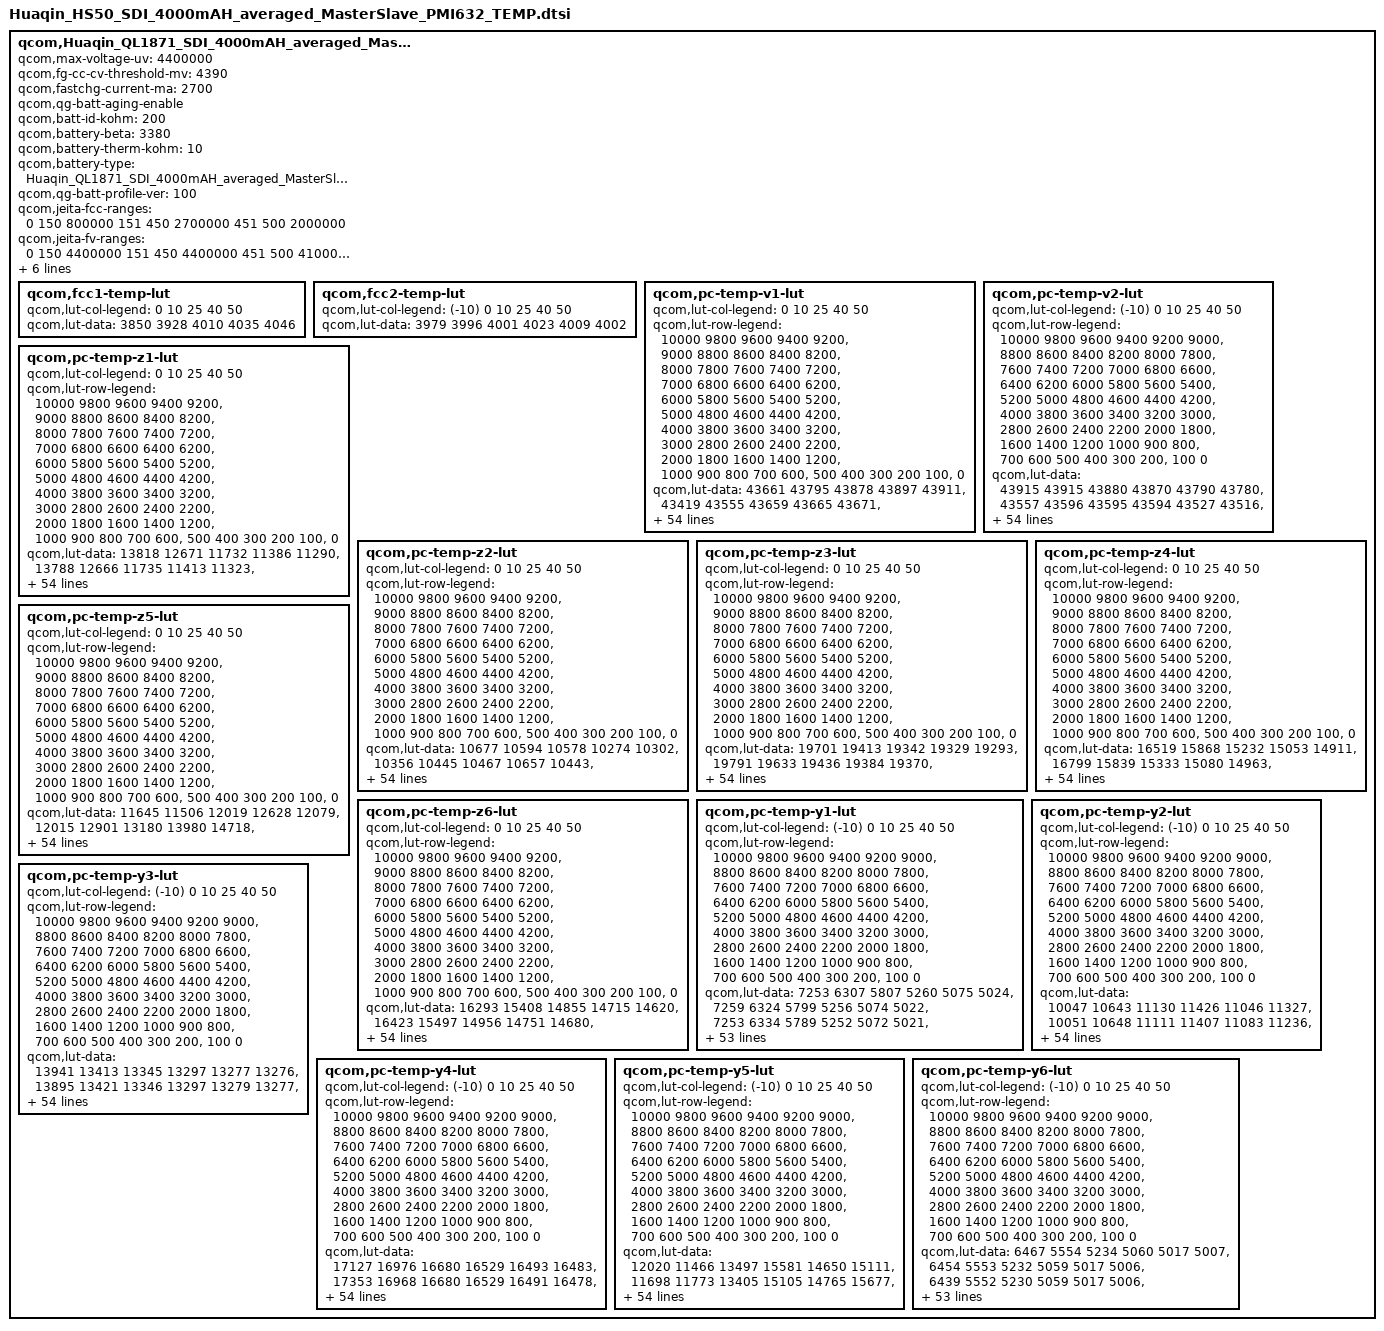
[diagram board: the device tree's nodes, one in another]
qcom,Huaqin_QL1871_SDI_4000mAH_averaged_MasterSlave_PMI632 {
        /* Huaqin_QL1871_SDI_4000mAH_averaged_MasterSlave_PMI632 */
	qcom,max-voltage-uv = <4400000>;
	qcom,fg-cc-cv-threshold-mv = <4390>;
	qcom,fastchg-current-ma = <2700>;
	/* HS60 add for SR-ZQL1695-01-357 Import battery aging by gaochao at 2019/08/29 start */
	qcom,qg-batt-aging-enable;
	/* HS60 add for SR-ZQL1695-01-357 Import battery aging by gaochao at 2019/08/29 end */
	qcom,batt-id-kohm = <200>;
	qcom,battery-beta = <3380>;
	qcom,battery-therm-kohm = <10>;
	qcom,battery-type = "Huaqin_QL1871_SDI_4000mAH_averaged_MasterSlave_PMI632";
	qcom,qg-batt-profile-ver = <100>;

	qcom,jeita-fcc-ranges = <0   150   800000
				 151 450  2700000
				 451 500  2000000>;
	qcom,jeita-fv-ranges =  <0   150  4400000
				 151 450  4400000
				 451 500  4100000>;

	/* HS60 add for SR-ZQL1695-01-357 Import battery aging by gaochao at 2019/08/29 start */
	qcom,vfloat-ranges = <0 299 4400000
	                      300 399 4380000
                              400 699 4360000
                              700 999 4340000
                              1000 9999 4290000>;

	qcom,vbat-rechg-ranges = <0 299 4330000
                                  300 399 4310000
                                  400 699 4290000
                                  700 999 4270000
                                  1000 9999 4220000>;
	/* HS60 add for SR-ZQL1695-01-357 Import battery aging by gaochao at 2019/08/29 end */

	/* COOL = 15 DegC, WARM = 45 DegC */
	qcom,jeita-soft-thresholds = <0x2554 0xFDC>;
	/* COLD = 0 DegC, HOT = 50 DegC */
	/* Huaqin add for HS70-733 modify jeita-hard-thresholds to 50 by qianyingdong at 2019/11/26 start */
	qcom,jeita-hard-thresholds = <0x36B9 0xDBF>;
	/* Huaqin add for HS70-733 modify jeita-hard-thresholds to 50 by qianyingdong at 2019/11/26 end */

	qcom,fcc1-temp-lut {
		qcom,lut-col-legend = <0 10 25 40 50>;
		qcom,lut-data = <3850 3928 4010 4035 4046>;
	};

	qcom,fcc2-temp-lut {
		qcom,lut-col-legend = <(-10) 0 10 25 40 50>;
		qcom,lut-data = <3979 3996 4001 4023 4009 4002>;
	};

	qcom,pc-temp-v1-lut {
		qcom,lut-col-legend = <0 10 25 40 50>;
		qcom,lut-row-legend = <10000 9800 9600 9400 9200>,
			<9000 8800 8600 8400 8200>,
			<8000 7800 7600 7400 7200>,
			<7000 6800 6600 6400 6200>,
			<6000 5800 5600 5400 5200>,
			<5000 4800 4600 4400 4200>,
			<4000 3800 3600 3400 3200>,
			<3000 2800 2600 2400 2200>,
			<2000 1800 1600 1400 1200>,
			<1000 900 800 700 600>,
			<500 400 300 200 100>,
			<0>;
		qcom,lut-data = <43661 43795 43878 43897 43911>,
			<43419 43555 43659 43665 43671>,
			<43173 43315 43415 43437 43445>,
			<42929 43074 43175 43208 43219>,
			<42691 42834 42936 42974 42988>,
			<42457 42597 42698 42737 42755>,
			<42230 42363 42460 42501 42522>,
			<42009 42134 42223 42263 42289>,
			<41794 41908 41992 42030 42057>,
			<41583 41688 41766 41801 41825>,
			<41375 41474 41543 41576 41596>,
			<41175 41266 41327 41353 41373>,
			<40992 41066 41114 41133 41155>,
			<40814 40880 40907 40922 40944>,
			<40604 40693 40702 40719 40738>,
			<40340 40479 40500 40523 40539>,
			<40092 40239 40294 40325 40346>,
			<39926 40032 40093 40127 40158>,
			<39795 39880 39921 39948 39980>,
			<39666 39744 39782 39796 39818>,
			<39534 39595 39634 39644 39656>,
			<39402 39439 39439 39452 39468>,
			<39266 39271 39222 39232 39257>,
			<39126 39058 39036 39041 39065>,
			<38985 38838 38871 38879 38896>,
			<38839 38699 38729 38737 38746>,
			<38696 38607 38618 38619 38623>,
			<38587 38532 38524 38517 38519>,
			<38501 38463 38435 38423 38423>,
			<38430 38400 38351 38334 38331>,
			<38372 38341 38278 38254 38248>,
			<38324 38283 38216 38181 38172>,
			<38282 38231 38161 38116 38102>,
			<38248 38185 38111 38060 38039>,
			<38217 38145 38067 38013 37986>,
			<38183 38107 38025 37968 37932>,
			<38151 38076 37987 37918 37866>,
			<38110 38039 37948 37864 37793>,
			<38048 37978 37889 37795 37714>,
			<37966 37882 37795 37707 37631>,
			<37866 37774 37685 37603 37535>,
			<37738 37652 37571 37483 37415>,
			<37593 37514 37440 37345 37274>,
			<37427 37351 37272 37185 37115>,
			<37292 37218 37135 37053 36989>,
			<37211 37137 37057 36978 36917>,
			<37182 37117 37039 36961 36897>,
			<37162 37097 37022 36947 36883>,
			<37139 37075 37006 36923 36860>,
			<37062 37001 36912 36806 36714>,
			<36752 36685 36587 36465 36364>,
			<36288 36221 36125 35998 35895>,
			<35683 35617 35522 35390 35284>,
			<34852 34785 34689 34552 34445>,
			<33517 33454 33362 33219 33100>,
			<30000 30000 30000 30000 30000>;
	};

	qcom,pc-temp-v2-lut {
		qcom,lut-col-legend = <(-10) 0 10 25 40 50>;
		qcom,lut-row-legend = <10000 9800 9600 9400 9200 9000>,
			<8800 8600 8400 8200 8000 7800>,
			<7600 7400 7200 7000 6800 6600>,
			<6400 6200 6000 5800 5600 5400>,
			<5200 5000 4800 4600 4400 4200>,
			<4000 3800 3600 3400 3200 3000>,
			<2800 2600 2400 2200 2000 1800>,
			<1600 1400 1200 1000 900 800>,
			<700 600 500 400 300 200>,
			<100 0>;
		qcom,lut-data = <43915 43915 43880 43870 43790 43780>,
			<43557 43596 43595 43594 43527 43516>,
			<43224 43298 43325 43329 43271 43261>,
			<42918 43023 43068 43077 43026 43016>,
			<42636 42772 42825 42838 42791 42783>,
			<42373 42528 42588 42602 42558 42551>,
			<42134 42286 42352 42366 42325 42319>,
			<41908 42050 42119 42131 42092 42087>,
			<41668 41822 41891 41901 41863 41858>,
			<41404 41602 41666 41675 41636 41632>,
			<41183 41388 41445 41450 41413 41409>,
			<41052 41180 41231 41228 41194 41190>,
			<40940 40977 41022 41008 40979 40975>,
			<40728 40768 40822 40801 40773 40769>,
			<40295 40557 40631 40604 40574 40570>,
			<39892 40329 40428 40405 40378 40376>,
			<39659 40047 40190 40195 40176 40186>,
			<39477 39753 39939 39991 39980 40001>,
			<39307 39532 39717 39817 39807 39827>,
			<39153 39364 39515 39668 39655 39665>,
			<39004 39205 39325 39499 39489 39492>,
			<38844 39042 39139 39271 39274 39278>,
			<38685 38884 38965 39035 39047 39055>,
			<38540 38737 38810 38852 38863 38871>,
			<38403 38598 38670 38695 38703 38713>,
			<38286 38470 38544 38562 38566 38576>,
			<38196 38353 38431 38449 38454 38460>,
			<38122 38245 38327 38348 38356 38358>,
			<38054 38145 38232 38254 38264 38264>,
			<37993 38046 38141 38166 38178 38178>,
			<37936 37965 38057 38087 38100 38100>,
			<37877 37904 37974 38016 38031 38029>,
			<37820 37854 37898 37951 37966 37963>,
			<37762 37808 37837 37889 37897 37892>,
			<37705 37769 37787 37833 37827 37817>,
			<37648 37730 37743 37772 37749 37732>,
			<37590 37687 37707 37706 37657 37623>,
			<37531 37642 37672 37635 37560 37504>,
			<37472 37588 37621 37563 37474 37407>,
			<37413 37527 37547 37489 37397 37325>,
			<37352 37451 37460 37403 37310 37238>,
			<37287 37336 37359 37300 37204 37133>,
			<37217 37207 37239 37176 37083 37015>,
			<37143 37100 37086 37024 36929 36866>,
			<37058 37008 36980 36922 36847 36787>,
			<36951 36921 36920 36885 36816 36757>,
			<36891 36885 36898 36871 36801 36739>,
			<36819 36844 36875 36847 36777 36718>,
			<36724 36784 36829 36797 36721 36660>,
			<36570 36654 36695 36625 36515 36432>,
			<36307 36345 36331 36235 36079 36005>,
			<35877 35840 35790 35679 35518 35451>,
			<35251 35156 35075 34946 34779 34714>,
			<34320 34185 34076 33870 33733 33705>,
			<32555 32499 32426 32581 32224 32191>,
			<27858 27337 27147 27137 27088 27140>;
	};

	qcom,pc-temp-z1-lut {
		qcom,lut-col-legend = <0 10 25 40 50>;
		qcom,lut-row-legend = <10000 9800 9600 9400 9200>,
			<9000 8800 8600 8400 8200>,
			<8000 7800 7600 7400 7200>,
			<7000 6800 6600 6400 6200>,
			<6000 5800 5600 5400 5200>,
			<5000 4800 4600 4400 4200>,
			<4000 3800 3600 3400 3200>,
			<3000 2800 2600 2400 2200>,
			<2000 1800 1600 1400 1200>,
			<1000 900 800 700 600>,
			<500 400 300 200 100>,
			<0>;
		qcom,lut-data = <13818 12671 11732 11386 11290>,
			<13788 12666 11735 11413 11323>,
			<13800 12659 11723 11407 11324>,
			<13812 12648 11714 11403 11323>,
			<13807 12638 11709 11401 11320>,
			<13797 12632 11704 11399 11318>,
			<13787 12622 11700 11397 11316>,
			<13773 12616 11696 11396 11315>,
			<13761 12611 11693 11395 11315>,
			<13757 12607 11692 11394 11315>,
			<13747 12604 11690 11393 11315>,
			<13740 12602 11689 11393 11315>,
			<13739 12598 11688 11393 11315>,
			<13737 12589 11687 11393 11316>,
			<13730 12577 11684 11392 11316>,
			<13701 12566 11682 11392 11317>,
			<13676 12553 11681 11392 11318>,
			<13678 12548 11680 11392 11319>,
			<13691 12550 11681 11392 11321>,
			<13698 12557 11684 11395 11325>,
			<13701 12564 11688 11398 11329>,
			<13703 12573 11690 11401 11330>,
			<13707 12582 11692 11403 11331>,
			<13712 12589 11695 11406 11332>,
			<13718 12594 11701 11410 11334>,
			<13724 12596 11707 11414 11337>,
			<13730 12598 11713 11417 11340>,
			<13735 12599 11719 11420 11343>,
			<13742 12602 11724 11424 11346>,
			<13748 12608 11729 11426 11348>,
			<13744 12610 11733 11429 11351>,
			<13732 12609 11737 11432 11354>,
			<13727 12609 11740 11435 11357>,
			<13724 12614 11744 11438 11359>,
			<13721 12623 11748 11440 11361>,
			<13730 12630 11753 11443 11363>,
			<13754 12635 11758 11446 11366>,
			<13771 12640 11764 11449 11369>,
			<13769 12648 11769 11452 11372>,
			<13760 12657 11773 11455 11374>,
			<13760 12662 11778 11457 11376>,
			<13774 12663 11781 11459 11378>,
			<13780 12664 11784 11460 11379>,
			<13776 12666 11787 11462 11379>,
			<13774 12672 11791 11464 11380>,
			<13760 12671 11792 11465 11381>,
			<13767 12664 11792 11464 11381>,
			<13757 12656 11793 11466 11380>,
			<13749 12655 11795 11467 11381>,
			<13736 12675 11798 11471 11385>,
			<13771 12690 11810 11477 11392>,
			<13785 12703 11819 11486 11401>,
			<13816 12733 11837 11498 11413>,
			<13844 12772 11864 11516 11429>,
			<13844 12772 11864 11516 11429>,
			<13844 12772 11864 11516 11429>;
	};

	qcom,pc-temp-z2-lut {
		qcom,lut-col-legend = <0 10 25 40 50>;
		qcom,lut-row-legend = <10000 9800 9600 9400 9200>,
			<9000 8800 8600 8400 8200>,
			<8000 7800 7600 7400 7200>,
			<7000 6800 6600 6400 6200>,
			<6000 5800 5600 5400 5200>,
			<5000 4800 4600 4400 4200>,
			<4000 3800 3600 3400 3200>,
			<3000 2800 2600 2400 2200>,
			<2000 1800 1600 1400 1200>,
			<1000 900 800 700 600>,
			<500 400 300 200 100>,
			<0>;
		qcom,lut-data = <10677 10594 10578 10274 10302>,
			<10356 10445 10467 10657 10443>,
			<10279 10370 10580 11118 10963>,
			<10242 10331 10626 11319 11341>,
			<10232 10313 10636 11276 11357>,
			<10227 10320 10644 11222 11364>,
			<10225 10341 10655 11221 11358>,
			<10233 10362 10668 11244 11314>,
			<10245 10378 10704 11260 11289>,
			<10252 10397 10864 11250 11296>,
			<10264 10440 10983 11233 11304>,
			<10278 10513 10991 11226 11285>,
			<10296 10547 10997 11217 11181>,
			<10314 10550 10986 11197 11107>,
			<10317 10547 10902 11071 11097>,
			<10304 10537 10839 10937 11087>,
			<10292 10521 10855 10940 10971>,
			<10314 10510 10886 10983 10607>,
			<10375 10512 10879 10990 10429>,
			<10409 10517 10767 10781 10448>,
			<10413 10503 10686 10574 10480>,
			<10414 10451 10715 10637 10506>,
			<10407 10404 10769 10821 10530>,
			<10374 10377 10789 10899 10562>,
			<10348 10358 10789 10895 10623>,
			<10312 10359 10787 10879 10675>,
			<10258 10391 10799 10827 10613>,
			<10244 10425 10813 10730 10420>,
			<10251 10449 10791 10681 10342>,
			<10262 10470 10700 10660 10345>,
			<10276 10473 10631 10651 10349>,
			<10298 10455 10618 10655 10352>,
			<10329 10440 10611 10668 10355>,
			<10393 10444 10613 10681 10364>,
			<10461 10457 10638 10694 10428>,
			<10489 10467 10671 10713 10521>,
			<10502 10483 10701 10775 10671>,
			<10507 10503 10737 10881 10881>,
			<10499 10519 10784 10935 10930>,
			<10487 10537 10855 10971 10823>,
			<10490 10555 10926 10990 10722>,
			<10522 10569 11205 10987 10671>,
			<10543 10586 11471 10978 10628>,
			<10559 10605 11090 10972 10672>,
			<10833 10729 10954 10910 10649>,
			<11357 10807 10941 10882 10581>,
			<11377 10985 10949 10671 10536>,
			<11079 11031 10900 10641 10529>,
			<10708 11077 10891 10678 10709>,
			<10841 11043 11086 10837 10523>,
			<11457 11256 11133 10586 10318>,
			<10640 11336 11073 10496 10275>,
			<10459 11341 10836 10428 10222>,
			<10216 11271 10756 10301 10190>,
			<10216 11271 10756 10301 10190>,
			<10216 11271 10756 10301 10190>;
	};

	qcom,pc-temp-z3-lut {
		qcom,lut-col-legend = <0 10 25 40 50>;
		qcom,lut-row-legend = <10000 9800 9600 9400 9200>,
			<9000 8800 8600 8400 8200>,
			<8000 7800 7600 7400 7200>,
			<7000 6800 6600 6400 6200>,
			<6000 5800 5600 5400 5200>,
			<5000 4800 4600 4400 4200>,
			<4000 3800 3600 3400 3200>,
			<3000 2800 2600 2400 2200>,
			<2000 1800 1600 1400 1200>,
			<1000 900 800 700 600>,
			<500 400 300 200 100>,
			<0>;
		qcom,lut-data = <19701 19413 19342 19329 19293>,
			<19791 19633 19436 19384 19370>,
			<19928 19735 19525 19433 19407>,
			<20035 19781 19547 19453 19425>,
			<20060 19803 19543 19448 19422>,
			<20073 19797 19538 19441 19416>,
			<20078 19776 19530 19438 19412>,
			<20068 19756 19520 19438 19406>,
			<20051 19737 19513 19436 19402>,
			<20040 19717 19507 19426 19402>,
			<20023 19693 19501 19414 19401>,
			<20002 19667 19491 19411 19397>,
			<19971 19654 19479 19411 19383>,
			<19936 19649 19472 19409 19374>,
			<19928 19648 19466 19400 19373>,
			<19947 19649 19462 19388 19374>,
			<19964 19651 19458 19384 19367>,
			<19940 19652 19454 19381 19347>,
			<19871 19639 19449 19378 19335>,
			<19835 19622 19440 19367 19334>,
			<19831 19625 19435 19357 19334>,
			<19834 19653 19452 19359 19336>,
			<19852 19685 19485 19369 19341>,
			<19911 19716 19488 19381 19349>,
			<19964 19743 19454 19405 19374>,
			<20014 19744 19427 19424 19397>,
			<20074 19719 19444 19423 19394>,
			<20088 19696 19478 19419 19378>,
			<20075 19686 19496 19417 19370>,
			<20056 19677 19506 19416 19369>,
			<20034 19676 19511 19415 19367>,
			<20005 19682 19504 19412 19366>,
			<19968 19687 19490 19408 19365>,
			<19908 19683 19482 19402 19364>,
			<19848 19673 19477 19392 19359>,
			<19822 19667 19472 19384 19355>,
			<19814 19659 19465 19380 19357>,
			<19812 19651 19458 19376 19359>,
			<19827 19651 19454 19374 19359>,
			<19851 19651 19452 19374 19353>,
			<19852 19651 19449 19374 19349>,
			<19822 19640 19437 19372 19349>,
			<19805 19625 19428 19371 19349>,
			<19794 19615 19432 19378 19358>,
			<19665 19569 19426 19372 19353>,
			<19493 19538 19415 19362 19336>,
			<19456 19479 19395 19344 19336>,
			<19371 19469 19396 19339 19334>,
			<19326 19462 19359 19336 19314>,
			<19344 19472 19375 19327 19341>,
			<19451 19437 19364 19345 19357>,
			<19343 19418 19353 19348 19361>,
			<19346 19395 19343 19345 19364>,
			<19353 19381 19351 19356 19347>,
			<19353 19381 19351 19356 19347>,
			<19353 19381 19351 19356 19347>;
	};

	qcom,pc-temp-z4-lut {
		qcom,lut-col-legend = <0 10 25 40 50>;
		qcom,lut-row-legend = <10000 9800 9600 9400 9200>,
			<9000 8800 8600 8400 8200>,
			<8000 7800 7600 7400 7200>,
			<7000 6800 6600 6400 6200>,
			<6000 5800 5600 5400 5200>,
			<5000 4800 4600 4400 4200>,
			<4000 3800 3600 3400 3200>,
			<3000 2800 2600 2400 2200>,
			<2000 1800 1600 1400 1200>,
			<1000 900 800 700 600>,
			<500 400 300 200 100>,
			<0>;
		qcom,lut-data = <16519 15868 15232 15053 14911>,
			<16799 15839 15333 15080 14963>,
			<16583 15778 15298 15034 14922>,
			<16307 15632 15250 14987 14880>,
			<16126 15472 15161 14951 14859>,
			<15972 15356 15084 14919 14844>,
			<15842 15255 15057 14899 14833>,
			<15731 15202 15040 14885 14825>,
			<15637 15176 15019 14873 14817>,
			<15558 15159 14991 14865 14806>,
			<15486 15150 14967 14857 14795>,
			<15441 15143 14952 14846 14789>,
			<15422 15134 14941 14831 14787>,
			<15409 15115 14928 14820 14783>,
			<15408 15093 14914 14811 14770>,
			<15424 15078 14898 14803 14754>,
			<15439 15068 14878 14791 14751>,
			<15429 15054 14858 14776 14757>,
			<15393 15019 14842 14766 14759>,
			<15364 14981 14828 14763 14750>,
			<15331 14970 14820 14765 14741>,
			<15295 14965 14857 14813 14768>,
			<15271 14963 14943 14928 14861>,
			<15231 15048 15024 14972 14904>,
			<15204 15186 15119 14962 14890>,
			<15202 15215 15173 14947 14870>,
			<15205 15203 15137 14929 14860>,
			<15207 15184 15058 14903 14853>,
			<15209 15153 15002 14878 14844>,
			<15210 15108 14959 14855 14827>,
			<15204 15067 14926 14833 14808>,
			<15191 15026 14904 14815 14791>,
			<15186 14991 14886 14799 14774>,
			<15206 14971 14870 14790 14763>,
			<15232 14956 14853 14784 14754>,
			<15233 14944 14845 14781 14749>,
			<15212 14931 14846 14792 14764>,
			<15193 14922 14848 14816 14797>,
			<15160 14926 14855 14829 14807>,
			<15113 14940 14889 14837 14805>,
			<15099 14946 14911 14840 14800>,
			<15110 14937 14894 14831 14792>,
			<15108 14932 14876 14818 14784>,
			<15083 14933 14884 14819 14785>,
			<15086 14912 14870 14814 14782>,
			<15183 14887 14828 14788 14764>,
			<15208 14919 14807 14773 14741>,
			<15284 14905 14765 14738 14707>,
			<15324 14897 14769 14712 14698>,
			<15298 14896 14788 14760 14713>,
			<15212 14978 14845 14761 14710>,
			<15357 15010 14861 14760 14706>,
			<15371 15044 14878 14764 14704>,
			<15387 15071 14875 14756 14721>,
			<15387 15071 14875 14756 14721>,
			<15387 15071 14875 14756 14721>;
	};

	qcom,pc-temp-z5-lut {
		qcom,lut-col-legend = <0 10 25 40 50>;
		qcom,lut-row-legend = <10000 9800 9600 9400 9200>,
			<9000 8800 8600 8400 8200>,
			<8000 7800 7600 7400 7200>,
			<7000 6800 6600 6400 6200>,
			<6000 5800 5600 5400 5200>,
			<5000 4800 4600 4400 4200>,
			<4000 3800 3600 3400 3200>,
			<3000 2800 2600 2400 2200>,
			<2000 1800 1600 1400 1200>,
			<1000 900 800 700 600>,
			<500 400 300 200 100>,
			<0>;
		qcom,lut-data = <11645 11506 12019 12628 12079>,
			<12015 12901 13180 13980 14718>,
			<12485 13711 14354 15043 16250>,
			<12910 14153 14996 15687 17211>,
			<13130 14493 15377 15958 17506>,
			<13294 14877 15603 16152 17636>,
			<13403 15247 15683 16420 17621>,
			<13510 15358 15699 16751 17513>,
			<13624 15301 15700 16884 17484>,
			<13754 15195 15739 16595 17781>,
			<14018 14976 15754 16234 18172>,
			<14186 14598 15688 16305 18062>,
			<14067 14431 15591 16683 17177>,
			<13846 14512 15492 16846 16642>,
			<13776 14646 15313 16443 17101>,
			<13895 14735 15191 15966 17712>,
			<14007 14805 15383 16102 17447>,
			<13904 14894 15879 16686 16119>,
			<13642 15147 16416 17042 15455>,
			<13536 15622 17039 17032 15868>,
			<13752 16419 17920 16957 16375>,
			<14097 18060 20111 16915 16149>,
			<14616 19903 22940 16758 15187>,
			<16134 22075 22961 16566 14752>,
			<17579 24089 18536 15907 15088>,
			<19474 24063 15216 15325 15470>,
			<21824 21178 15287 15360 15375>,
			<22357 18541 15549 15577 15000>,
			<21698 17629 15988 15892 14862>,
			<20763 16997 17079 16520 15192>,
			<19904 16933 18109 17327 15744>,
			<18957 17647 18601 18258 16370>,
			<17937 18423 18997 19294 17179>,
			<16627 18801 19720 19909 18043>,
			<15451 19110 21128 20366 19174>,
			<15013 19186 21996 20602 19923>,
			<15031 19089 21993 20375 19865>,
			<15192 19094 21931 19841 19606>,
			<15841 19541 21696 19289 19180>,
			<16813 20344 20681 18428 17971>,
			<17009 20650 19477 17754 17034>,
			<16364 19890 18215 17550 16962>,
			<16168 19022 17324 17420 16941>,
			<16499 18508 17448 17311 17171>,
			<15383 17740 17511 16733 16540>,
			<13022 16959 17460 16376 15218>,
			<12650 14581 16531 15418 15729>,
			<11930 14318 17413 16034 17197>,
			<11609 14168 15255 17651 16302>,
			<11797 14563 15644 14481 16443>,
			<12685 13427 13675 14295 16843>,
			<11685 12907 13103 14148 16900>,
			<11616 12471 12667 13770 16957>,
			<11545 12180 12701 14099 14486>,
			<11545 12180 12701 14099 14486>,
			<11545 12180 12701 14099 14486>;
	};

	qcom,pc-temp-z6-lut {
		qcom,lut-col-legend = <0 10 25 40 50>;
		qcom,lut-row-legend = <10000 9800 9600 9400 9200>,
			<9000 8800 8600 8400 8200>,
			<8000 7800 7600 7400 7200>,
			<7000 6800 6600 6400 6200>,
			<6000 5800 5600 5400 5200>,
			<5000 4800 4600 4400 4200>,
			<4000 3800 3600 3400 3200>,
			<3000 2800 2600 2400 2200>,
			<2000 1800 1600 1400 1200>,
			<1000 900 800 700 600>,
			<500 400 300 200 100>,
			<0>;
		qcom,lut-data = <16293 15408 14855 14715 14620>,
			<16423 15497 14956 14751 14680>,
			<16369 15513 14975 14756 14681>,
			<16290 15465 14973 14757 14681>,
			<16219 15401 14933 14743 14675>,
			<16143 15344 14891 14720 14663>,
			<16073 15285 14873 14709 14654>,
			<16011 15247 14861 14702 14647>,
			<15955 15223 14847 14696 14641>,
			<15909 15204 14832 14686 14636>,
			<15870 15187 14818 14677 14631>,
			<15836 15173 14806 14669 14625>,
			<15800 15159 14795 14663 14617>,
			<15769 15143 14785 14657 14610>,
			<15763 15130 14776 14648 14604>,
			<15771 15121 14766 14638 14598>,
			<15779 15116 14755 14630 14591>,
			<15763 15108 14744 14622 14583>,
			<15717 15086 14734 14615 14577>,
			<15686 15062 14722 14608 14572>,
			<15671 15060 14716 14604 14569>,
			<15661 15073 14743 14623 14581>,
			<15663 15093 14798 14679 14625>,
			<15680 15150 14833 14708 14651>,
			<15700 15222 14857 14716 14659>,
			<15730 15236 14869 14720 14663>,
			<15765 15221 14862 14716 14660>,
			<15773 15202 14847 14702 14648>,
			<15770 15183 14834 14690 14638>,
			<15764 15162 14823 14680 14630>,
			<15753 15146 14811 14670 14622>,
			<15734 15133 14797 14661 14614>,
			<15715 15122 14783 14652 14606>,
			<15697 15112 14772 14644 14600>,
			<15681 15103 14763 14635 14593>,
			<15672 15096 14757 14630 14589>,
			<15664 15089 14753 14633 14596>,
			<15659 15084 14751 14641 14612>,
			<15658 15087 14753 14646 14616>,
			<15658 15098 14766 14650 14613>,
			<15657 15102 14775 14651 14608>,
			<15653 15095 14764 14647 14604>,
			<15648 15088 14753 14641 14601>,
			<15640 15086 14758 14645 14606>,
			<15575 15058 14750 14641 14604>,
			<15540 15032 14725 14624 14587>,
			<15531 15016 14707 14608 14577>,
			<15520 15006 14689 14589 14561>,
			<15515 15000 14671 14577 14546>,
			<15523 15010 14689 14593 14568>,
			<15554 15033 14710 14606 14577>,
			<15571 15043 14715 14609 14580>,
			<15597 15056 14720 14612 14584>,
			<15636 15075 14729 14619 14587>,
			<15636 15075 14729 14619 14587>,
			<15636 15075 14729 14619 14587>;
	};

	qcom,pc-temp-y1-lut {
		qcom,lut-col-legend = <(-10) 0 10 25 40 50>;
		qcom,lut-row-legend = <10000 9800 9600 9400 9200 9000>,
			<8800 8600 8400 8200 8000 7800>,
			<7600 7400 7200 7000 6800 6600>,
			<6400 6200 6000 5800 5600 5400>,
			<5200 5000 4800 4600 4400 4200>,
			<4000 3800 3600 3400 3200 3000>,
			<2800 2600 2400 2200 2000 1800>,
			<1600 1400 1200 1000 900 800>,
			<700 600 500 400 300 200>,
			<100 0>;
		qcom,lut-data = <7253 6307 5807 5260 5075 5024>,
			<7259 6324 5799 5256 5074 5022>,
			<7253 6334 5789 5252 5072 5021>,
			<7238 6337 5779 5249 5071 5019>,
			<7221 6337 5771 5245 5069 5018>,
			<7206 6336 5766 5241 5067 5017>,
			<7186 6333 5765 5236 5066 5016>,
			<7164 6326 5764 5232 5064 5016>,
			<7158 6318 5761 5230 5063 5016>,
			<7150 6307 5751 5228 5062 5015>,
			<7147 6301 5745 5227 5062 5015>,
			<7160 6308 5741 5224 5061 5014>,
			<7181 6320 5735 5222 5061 5014>,
			<7197 6323 5730 5221 5060 5014>,
			<7212 6322 5723 5220 5060 5016>,
			<7220 6323 5720 5220 5059 5018>,
			<7202 6332 5727 5221 5060 5018>,
			<7167 6343 5738 5223 5062 5018>,
			<7158 6345 5739 5225 5062 5018>,
			<7176 6340 5735 5227 5063 5019>,
			<7191 6336 5732 5229 5063 5020>,
			<7179 6332 5733 5231 5064 5020>,
			<7159 6329 5736 5232 5066 5021>,
			<7151 6328 5739 5234 5068 5022>,
			<7146 6330 5744 5237 5069 5024>,
			<7140 6331 5748 5240 5071 5026>,
			<7133 6332 5748 5243 5073 5028>,
			<7127 6333 5748 5247 5075 5029>,
			<7125 6333 5751 5249 5077 5031>,
			<7134 6328 5758 5251 5079 5033>,
			<7142 6324 5763 5254 5081 5034>,
			<7128 6323 5762 5257 5083 5036>,
			<7102 6321 5760 5261 5085 5039>,
			<7097 6318 5760 5266 5087 5041>,
			<7109 6312 5764 5271 5090 5043>,
			<7120 6307 5766 5274 5093 5045>,
			<7120 6303 5765 5277 5095 5046>,
			<7113 6300 5764 5279 5097 5046>,
			<7105 6299 5766 5282 5098 5047>,
			<7083 6300 5777 5284 5098 5049>,
			<7060 6303 5785 5287 5099 5051>,
			<7042 6315 5784 5291 5101 5053>,
			<7030 6326 5782 5295 5104 5055>,
			<7042 6298 5784 5300 5107 5058>,
			<7054 6308 5797 5306 5110 5060>,
			<7111 6340 5804 5311 5112 5062>,
			<7127 6350 5804 5314 5113 5063>,
			<7124 6342 5828 5317 5114 5062>,
			<7110 6348 5825 5319 5114 5062>,
			<7112 6335 5825 5321 5115 5064>,
			<7087 6325 5827 5327 5119 5067>,
			<7086 6327 5836 5339 5127 5075>,
			<7152 6337 5852 5358 5138 5084>,
			<7188 6347 5889 5379 5151 5096>,
			<7188 6347 5889 5379 5151 5096>,
			<7188 6347 5889 5379 5151 5096>;
	};

	qcom,pc-temp-y2-lut {
		qcom,lut-col-legend = <(-10) 0 10 25 40 50>;
		qcom,lut-row-legend = <10000 9800 9600 9400 9200 9000>,
			<8800 8600 8400 8200 8000 7800>,
			<7600 7400 7200 7000 6800 6600>,
			<6400 6200 6000 5800 5600 5400>,
			<5200 5000 4800 4600 4400 4200>,
			<4000 3800 3600 3400 3200 3000>,
			<2800 2600 2400 2200 2000 1800>,
			<1600 1400 1200 1000 900 800>,
			<700 600 500 400 300 200>,
			<100 0>;
		qcom,lut-data = <10047 10643 11130 11426 11046 11327>,
			<10051 10648 11111 11407 11083 11236>,
			<10061 10654 11089 11373 11117 11158>,
			<10076 10659 11067 11335 11145 11093>,
			<10094 10663 11049 11303 11165 11045>,
			<10115 10667 11040 11289 11173 11014>,
			<10137 10669 11037 11289 11166 11001>,
			<10164 10672 11036 11289 11155 11002>,
			<10234 10673 11037 11292 11158 11022>,
			<10433 10676 11044 11304 11183 11075>,
			<10566 10678 11046 11319 11208 11113>,
			<10560 10674 11027 11360 11246 11124>,
			<10546 10669 11001 11407 11289 11131>,
			<10551 10697 10996 11405 11290 11136>,
			<10605 10834 10999 11372 11259 11142>,
			<10682 10924 11006 11355 11240 11153>,
			<10795 10911 11036 11417 11325 11191>,
			<10933 10889 11081 11514 11474 11253>,
			<11016 10894 11100 11568 11583 11316>,
			<11073 10946 11107 11609 11681 11387>,
			<11101 11001 11117 11622 11725 11438>,
			<10715 11035 11149 11550 11684 11465>,
			<9968 11065 11197 11461 11603 11483>,
			<9730 11104 11243 11458 11515 11451>,
			<9698 11154 11294 11490 11401 11287>,
			<9683 11191 11324 11521 11347 11185>,
			<9678 11205 11324 11548 11458 11206>,
			<9675 11216 11320 11575 11622 11249>,
			<9672 11239 11324 11601 11682 11299>,
			<9670 11291 11331 11629 11708 11376>,
			<9668 11322 11340 11646 11733 11471>,
			<9667 11312 11352 11665 11774 11616>,
			<9665 11288 11363 11681 11813 11756>,
			<9664 11256 11363 11676 11831 11785>,
			<9662 11202 11350 11654 11842 11785>,
			<9661 11148 11332 11631 11845 11776>,
			<9660 11110 11305 11604 11744 11610>,
			<9659 11074 11269 11578 11603 11366>,
			<9658 11030 11241 11559 11567 11290>,
			<9658 10979 11219 11542 11558 11259>,
			<9657 10908 11193 11522 11540 11247>,
			<9657 10627 11151 11493 11447 11251>,
			<9656 10288 11107 11468 11352 11254>,
			<9656 9838 11077 11450 11287 11183>,
			<9655 9678 11001 11325 11171 11027>,
			<9655 9678 11040 11325 11158 11004>,
			<9655 9674 10995 11312 11171 10971>,
			<9655 9669 10942 11290 11160 11053>,
			<9655 9665 10890 11234 11156 11068>,
			<9654 9661 10842 11234 11130 10978>,
			<9654 9658 10757 11205 11108 10871>,
			<9653 9656 10621 11104 11032 10846>,
			<9653 9654 10486 10996 10943 10734>,
			<9651 9653 10354 10880 10866 10757>,
			<9651 9653 10354 10880 10866 10757>,
			<9651 9653 10354 10880 10866 10757>;
	};

	qcom,pc-temp-y3-lut {
		qcom,lut-col-legend = <(-10) 0 10 25 40 50>;
		qcom,lut-row-legend = <10000 9800 9600 9400 9200 9000>,
			<8800 8600 8400 8200 8000 7800>,
			<7600 7400 7200 7000 6800 6600>,
			<6400 6200 6000 5800 5600 5400>,
			<5200 5000 4800 4600 4400 4200>,
			<4000 3800 3600 3400 3200 3000>,
			<2800 2600 2400 2200 2000 1800>,
			<1600 1400 1200 1000 900 800>,
			<700 600 500 400 300 200>,
			<100 0>;
		qcom,lut-data = <13941 13413 13345 13297 13277 13276>,
			<13895 13421 13346 13297 13279 13277>,
			<13856 13432 13347 13297 13280 13279>,
			<13825 13443 13347 13297 13282 13280>,
			<13805 13452 13348 13297 13284 13282>,
			<13797 13459 13348 13298 13286 13283>,
			<13807 13462 13349 13298 13287 13285>,
			<13824 13465 13350 13299 13289 13286>,
			<13825 13467 13351 13301 13289 13287>,
			<13807 13471 13352 13307 13290 13289>,
			<13781 13477 13353 13310 13290 13289>,
			<13714 13491 13357 13308 13293 13289>,
			<13624 13508 13364 13304 13298 13289>,
			<13606 13508 13373 13304 13298 13290>,
			<13616 13492 13388 13305 13297 13294>,
			<13624 13477 13395 13307 13296 13297>,
			<13590 13470 13393 13307 13295 13295>,
			<13523 13464 13387 13308 13294 13292>,
			<13489 13455 13381 13311 13294 13292>,
			<13473 13440 13374 13319 13297 13292>,
			<13461 13428 13367 13323 13299 13293>,
			<13448 13422 13359 13317 13296 13289>,
			<13437 13417 13351 13309 13290 13284>,
			<13432 13411 13346 13303 13286 13281>,
			<13427 13402 13342 13298 13282 13279>,
			<13424 13395 13340 13297 13281 13278>,
			<13424 13392 13341 13297 13282 13278>,
			<13425 13389 13344 13299 13284 13278>,
			<13430 13384 13344 13299 13284 13278>,
			<13443 13372 13344 13299 13284 13279>,
			<13459 13365 13344 13300 13283 13279>,
			<13475 13366 13343 13300 13285 13280>,
			<13495 13367 13342 13302 13287 13281>,
			<13518 13370 13342 13302 13288 13282>,
			<13547 13381 13343 13303 13287 13282>,
			<13580 13391 13344 13304 13287 13282>,
			<13619 13397 13349 13303 13285 13280>,
			<13666 13403 13355 13303 13283 13276>,
			<13722 13410 13355 13302 13283 13276>,
			<13793 13419 13355 13301 13284 13277>,
			<13871 13424 13355 13301 13285 13278>,
			<13947 13413 13354 13301 13284 13279>,
			<14027 13402 13353 13301 13283 13280>,
			<14114 13426 13343 13299 13281 13280>,
			<14194 13461 13345 13300 13283 13282>,
			<14146 13443 13341 13302 13288 13286>,
			<14122 13470 13346 13308 13293 13288>,
			<14228 13505 13356 13312 13300 13295>,
			<14334 13566 13367 13322 13306 13297>,
			<14444 13635 13374 13318 13299 13290>,
			<14578 13733 13363 13316 13293 13289>,
			<14735 13919 13372 13321 13298 13292>,
			<14940 14236 13395 13330 13307 13294>,
			<15439 14557 13450 13347 13315 13303>,
			<15439 14557 13450 13347 13315 13303>,
			<15439 14557 13450 13347 13315 13303>;
	};

	qcom,pc-temp-y4-lut {
		qcom,lut-col-legend = <(-10) 0 10 25 40 50>;
		qcom,lut-row-legend = <10000 9800 9600 9400 9200 9000>,
			<8800 8600 8400 8200 8000 7800>,
			<7600 7400 7200 7000 6800 6600>,
			<6400 6200 6000 5800 5600 5400>,
			<5200 5000 4800 4600 4400 4200>,
			<4000 3800 3600 3400 3200 3000>,
			<2800 2600 2400 2200 2000 1800>,
			<1600 1400 1200 1000 900 800>,
			<700 600 500 400 300 200>,
			<100 0>;
		qcom,lut-data = <17127 16976 16680 16529 16493 16483>,
			<17353 16968 16680 16529 16491 16478>,
			<17496 16962 16681 16530 16490 16474>,
			<17575 16958 16685 16534 16490 16471>,
			<17608 16955 16689 16539 16489 16469>,
			<17615 16953 16695 16546 16489 16468>,
			<17565 16952 16701 16555 16492 16469>,
			<17474 16952 16709 16564 16497 16471>,
			<17426 16953 16719 16571 16503 16474>,
			<17386 16954 16736 16575 16513 16477>,
			<17365 16955 16748 16581 16521 16482>,
			<17550 16954 16751 16600 16525 16490>,
			<17865 16952 16754 16626 16528 16499>,
			<17872 16968 16764 16647 16536 16505>,
			<17438 17051 16794 16667 16554 16510>,
			<17117 17107 16812 16686 16572 16516>,
			<17141 17009 16802 16708 16587 16528>,
			<17191 16852 16778 16725 16601 16545>,
			<17201 16817 16747 16726 16618 16562>,
			<17181 16816 16696 16724 16637 16581>,
			<17165 16814 16657 16720 16645 16590>,
			<17168 16803 16637 16660 16611 16569>,
			<17176 16787 16624 16581 16556 16532>,
			<17174 16778 16619 16552 16527 16509>,
			<17147 16773 16618 16536 16507 16491>,
			<17122 16768 16618 16530 16499 16484>,
			<17116 16756 16616 16534 16501 16486>,
			<17113 16742 16615 16542 16507 16491>,
			<17112 16738 16617 16550 16515 16498>,
			<17110 16738 16621 16561 16531 16510>,
			<17108 16740 16624 16573 16547 16522>,
			<17110 16746 16622 16588 16562 16536>,
			<17112 16755 16620 16602 16573 16548>,
			<17115 16759 16620 16610 16574 16550>,
			<17119 16760 16627 16615 16571 16549>,
			<17125 16763 16637 16616 16567 16547>,
			<17136 16773 16650 16599 16544 16529>,
			<17156 16787 16664 16578 16517 16503>,
			<17179 16793 16665 16569 16510 16496>,
			<17207 16796 16663 16564 16508 16494>,
			<17241 16798 16661 16562 16507 16492>,
			<17284 16816 16660 16561 16509 16491>,
			<17332 16841 16660 16559 16510 16487>,
			<17368 16886 16651 16543 16496 16471>,
			<17377 16923 16648 16533 16495 16469>,
			<17233 16911 16648 16550 16510 16483>,
			<17163 16927 16675 16568 16520 16500>,
			<17175 16961 16704 16592 16537 16521>,
			<17194 16998 16735 16608 16550 16543>,
			<17195 17019 16747 16596 16529 16497>,
			<17176 16993 16721 16552 16497 16475>,
			<17157 16981 16721 16548 16499 16478>,
			<17150 17005 16748 16563 16510 16493>,
			<17270 17062 16792 16620 16595 16575>,
			<17270 17062 16792 16620 16595 16575>,
			<17270 17062 16792 16620 16595 16575>;
	};

	qcom,pc-temp-y5-lut {
		qcom,lut-col-legend = <(-10) 0 10 25 40 50>;
		qcom,lut-row-legend = <10000 9800 9600 9400 9200 9000>,
			<8800 8600 8400 8200 8000 7800>,
			<7600 7400 7200 7000 6800 6600>,
			<6400 6200 6000 5800 5600 5400>,
			<5200 5000 4800 4600 4400 4200>,
			<4000 3800 3600 3400 3200 3000>,
			<2800 2600 2400 2200 2000 1800>,
			<1600 1400 1200 1000 900 800>,
			<700 600 500 400 300 200>,
			<100 0>;
		qcom,lut-data = <12020 11466 13497 15581 14650 15111>,
			<11698 11773 13405 15105 14765 15677>,
			<11553 12145 13296 14650 14834 16107>,
			<11550 12526 13183 14228 14869 16406>,
			<11655 12859 13080 13848 14881 16582>,
			<11837 13089 13000 13522 14881 16639>,
			<12511 13226 12923 13195 14742 16551>,
			<13453 13351 12859 12944 14446 16352>,
			<13683 13579 12834 12969 14098 16113>,
			<13423 14150 12772 13237 13601 15771>,
			<13244 14542 12778 13390 13345 15369>,
			<13542 14592 13080 12991 13610 14782>,
			<14133 14626 13642 12428 14001 14223>,
			<14789 14889 14262 12304 13926 14193>,
			<16042 16054 15051 12274 13248 14512>,
			<16845 17111 15991 12268 12826 14712>,
			<15651 17671 17470 12551 12807 14212>,
			<13491 18062 18913 13189 12797 13455>,
			<12987 17854 19116 14583 12913 13342>,
			<13244 16357 18851 17523 13563 13510>,
			<13447 15299 18441 19020 14422 13784>,
			<13163 15329 17524 19116 15797 14690>,
			<12525 15453 16363 19129 17133 15808>,
			<12072 15371 15795 18568 17084 16009>,
			<11724 15040 15401 16781 16029 15955>,
			<11509 14831 15233 15918 15385 15860>,
			<11453 14980 15532 16045 15507 15402>,
			<11430 15213 16026 16201 15701 14769>,
			<11436 15099 16291 16181 15580 14560>,
			<11499 14187 16551 16121 15145 14477>,
			<11546 13529 16682 16164 14923 14447>,
			<11542 13484 16641 16393 15519 14638>,
			<11533 13493 16560 16734 16419 15046>,
			<11522 13631 16484 17277 16857 15577>,
			<11506 14262 16432 18114 17169 16417>,
			<11482 14826 16487 18430 17290 16860>,
			<11429 15108 17001 18261 17222 16421>,
			<11348 15432 17657 17940 17078 15688>,
			<11312 15838 17663 17376 16878 15330>,
			<11316 16494 17077 16442 16511 15108>,
			<11331 16875 16448 15778 16064 15018>,
			<11348 15346 16060 15375 15226 15096>,
			<11377 13203 15564 15158 14682 15298>,
			<11492 12201 14084 15106 14700 16515>,
			<11692 11948 13726 14789 14541 16622>,
			<11975 11806 13547 13950 13852 15356>,
			<12151 11950 13401 13952 14220 14807>,
			<12228 12008 13567 13774 14999 16240>,
			<12302 12154 13827 14472 16243 16259>,
			<12364 12288 14065 14326 15357 15618>,
			<12329 12121 13283 15027 14902 16711>,
			<11937 11923 13230 15773 16097 17703>,
			<11768 12002 13522 16891 19625 17544>,
			<11334 12043 15376 19867 21539 21920>,
			<11334 12043 15376 19867 21539 21920>,
			<11334 12043 15376 19867 21539 21920>;
	};

	qcom,pc-temp-y6-lut {
		qcom,lut-col-legend = <(-10) 0 10 25 40 50>;
		qcom,lut-row-legend = <10000 9800 9600 9400 9200 9000>,
			<8800 8600 8400 8200 8000 7800>,
			<7600 7400 7200 7000 6800 6600>,
			<6400 6200 6000 5800 5600 5400>,
			<5200 5000 4800 4600 4400 4200>,
			<4000 3800 3600 3400 3200 3000>,
			<2800 2600 2400 2200 2000 1800>,
			<1600 1400 1200 1000 900 800>,
			<700 600 500 400 300 200>,
			<100 0>;
		qcom,lut-data = <6467 5554 5234 5060 5017 5007>,
			<6454 5553 5232 5059 5017 5006>,
			<6439 5552 5230 5059 5017 5006>,
			<6424 5550 5228 5060 5018 5006>,
			<6409 5547 5226 5061 5019 5007>,
			<6392 5544 5225 5063 5020 5007>,
			<6376 5540 5226 5066 5022 5009>,
			<6358 5536 5226 5069 5024 5011>,
			<6336 5534 5227 5072 5027 5012>,
			<6306 5533 5230 5076 5029 5014>,
			<6289 5532 5233 5081 5032 5017>,
			<6303 5535 5236 5085 5036 5019>,
			<6329 5542 5239 5089 5039 5021>,
			<6321 5550 5246 5095 5043 5024>,
			<6224 5560 5263 5101 5047 5028>,
			<6140 5565 5272 5107 5051 5032>,
			<6120 5539 5268 5113 5054 5034>,
			<6109 5494 5258 5118 5058 5037>,
			<6101 5474 5246 5122 5063 5041>,
			<6096 5465 5227 5126 5070 5046>,
			<6091 5458 5210 5128 5073 5049>,
			<6082 5451 5198 5107 5061 5041>,
			<6070 5444 5189 5078 5041 5026>,
			<6064 5440 5185 5066 5030 5017>,
			<6060 5436 5183 5058 5021 5011>,
			<6058 5434 5182 5056 5018 5008>,
			<6065 5434 5183 5057 5020 5008>,
			<6082 5435 5186 5061 5023 5010>,
			<6100 5435 5188 5064 5026 5012>,
			<6122 5436 5191 5067 5030 5016>,
			<6146 5438 5193 5072 5034 5020>,
			<6171 5446 5194 5077 5040 5025>,
			<6197 5460 5194 5082 5045 5030>,
			<6227 5476 5195 5085 5046 5030>,
			<6261 5496 5200 5088 5045 5030>,
			<6299 5518 5205 5089 5044 5030>,
			<6342 5541 5214 5084 5036 5023>,
			<6390 5567 5224 5078 5027 5013>,
			<6445 5596 5229 5076 5026 5012>,
			<6507 5630 5232 5074 5026 5012>,
			<6575 5665 5234 5073 5027 5012>,
			<6648 5694 5240 5074 5027 5013>,
			<6725 5727 5244 5074 5026 5013>,
			<6804 5782 5245 5069 5021 5008>,
			<6870 5859 5255 5068 5023 5010>,
			<6818 5853 5253 5075 5031 5017>,
			<6789 5899 5270 5085 5038 5023>,
			<6875 5964 5292 5095 5047 5035>,
			<6962 6046 5318 5107 5055 5043>,
			<7051 6135 5337 5100 5045 5025>,
			<7151 6235 5339 5089 5032 5018>,
			<7273 6409 5381 5092 5037 5022>,
			<7447 6686 5455 5106 5048 5029>,
			<7918 6971 5580 5139 5080 5061>,
			<7918 6971 5580 5139 5080 5061>,
			<7918 6971 5580 5139 5080 5061>;
	};

};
